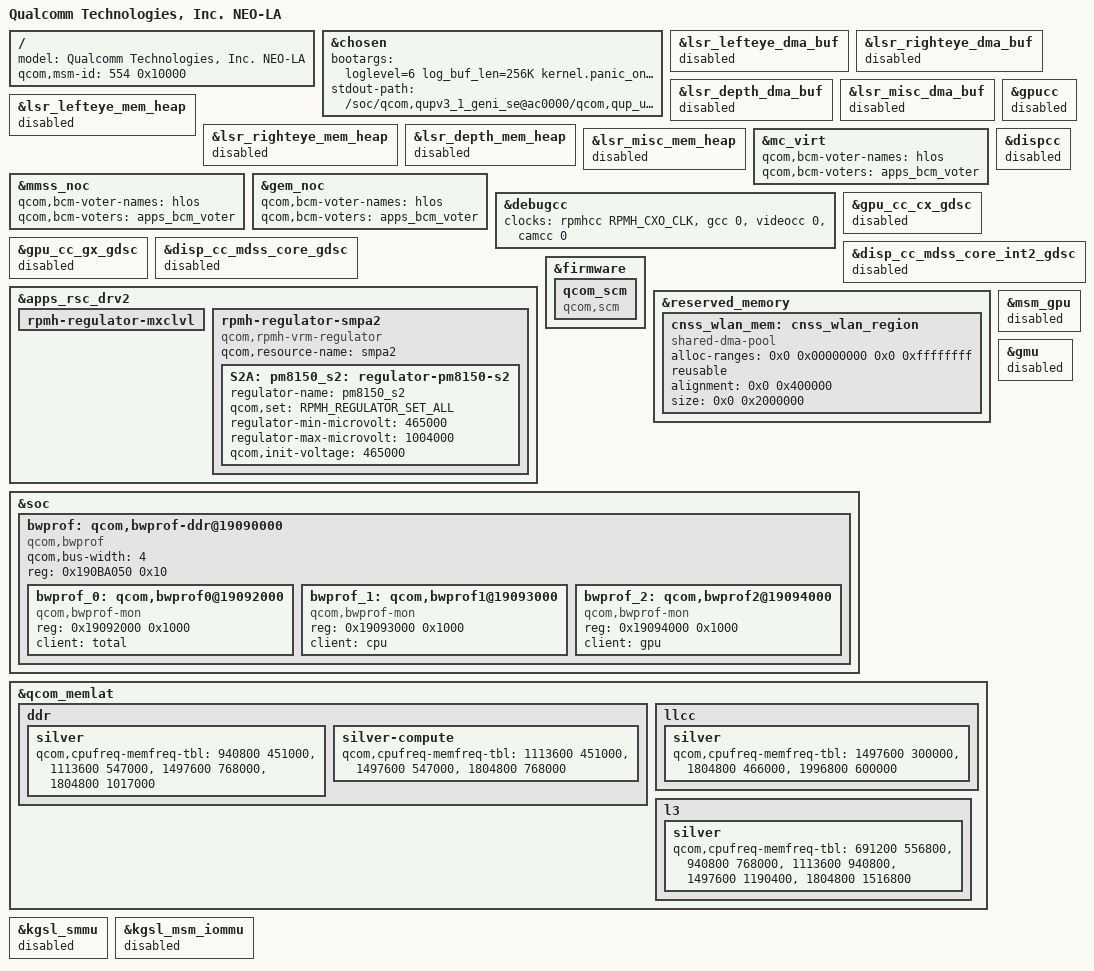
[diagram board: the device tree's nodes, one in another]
#include "neo.dtsi"
#include "neo_la-reserved-memory.dtsi"

/ {
	model = "Qualcomm Technologies, Inc. NEO-LA";
	qcom,msm-id = <554 0x10000>;
};

&chosen {
	bootargs = "loglevel=6 log_buf_len=256K kernel.panic_on_rcu_stall=1 loop.max_part=7 pcie_ports=compat service_locator.enable=1 msm_rtb.filter=0x237 allow_mismatched_32bit_el0 kasan=off rcupdate.rcu_expedited=1 rcu_nocbs=0-7 pstore.compress=none kpti=off swiotlb=noforce cgroup.memory=nokmem,nosocket allow_file_spec_access cpufreq.default_governor=performance disable_dma32=on ftrace_dump_on_oops";

	stdout-path = "/soc/qcom,qupv3_1_geni_se@ac0000/qcom,qup_uart@a94000:115200n8";
};

&lsr_lefteye_dma_buf {
	status = "disabled";
};

&lsr_righteye_dma_buf {
	status = "disabled";
};

&lsr_depth_dma_buf {
	status = "disabled";
};

&lsr_misc_dma_buf {
	status = "disabled";
};

&lsr_lefteye_mem_heap {
	status = "disabled";
};

&lsr_righteye_mem_heap {
	status = "disabled";
};

&lsr_depth_mem_heap {
	status = "disabled";
};

&lsr_misc_mem_heap {
	status = "disabled";
};

&mc_virt {
	qcom,bcm-voter-names = "hlos";
	qcom,bcm-voters = <&apps_bcm_voter>;
};

&mmss_noc {
	qcom,bcm-voter-names = "hlos";
	qcom,bcm-voters = <&apps_bcm_voter>;
};

&gem_noc {
	qcom,bcm-voter-names = "hlos";
	qcom,bcm-voters = <&apps_bcm_voter>;
};

&gpucc {
	status = "disabled";
};

&dispcc {
	status = "disabled";
};

&debugcc {
	/delete-property/ qcom,gpucc;
	/delete-property/ qcom,dispcc;
	clock-names = "xo_clk_src",
			"gcc",
			"videocc",
			"camcc";
	clocks = <&rpmhcc RPMH_CXO_CLK>,
		<&gcc 0>,
		<&videocc 0>,
		<&camcc 0>;
};

&gpu_cc_cx_gdsc {
	status = "disabled";
};

&gpu_cc_gx_gdsc {
	status = "disabled";
};

&disp_cc_mdss_core_gdsc {
	status = "disabled";
};

&disp_cc_mdss_core_int2_gdsc {
	status = "disabled";
};

&gpu_cc_gx_gdsc {
	/*
	 * Clocks uses GFX as its parent supply delete it as
	 * its not required on neo_la.
	 */
	/delete-property/ parent-supply;
};

&apps_rsc_drv2 {
	/* Delete GFX rail as it is not required on neo_la platform. */
	/delete-node/ rpmh-regulator-gfxlvl;

	rpmh-regulator-mxclvl {
		/delete-node/ regulator-pm8150-s8-gfx-voter-level;
	};

	rpmh-regulator-smpa2 {
		compatible = "qcom,rpmh-vrm-regulator";
		qcom,resource-name = "smpa2";
		S2A: pm8150_s2: regulator-pm8150-s2 {
			regulator-name = "pm8150_s2";
			qcom,set = <RPMH_REGULATOR_SET_ALL>;
			regulator-min-microvolt = <465000>;
			regulator-max-microvolt = <1004000>;
			qcom,init-voltage = <465000>;
		};
	};
};

&firmware {
	qcom_scm {
		compatible = "qcom,scm";
	};
};

&reserved_memory {
	cnss_wlan_mem: cnss_wlan_region {
		compatible = "shared-dma-pool";
		alloc-ranges = <0x0 0x00000000 0x0 0xffffffff>;
		reusable;
		alignment = <0x0 0x400000>;
		size = <0x0 0x2000000>;
	};
};

&soc {
	bwprof: qcom,bwprof-ddr@19090000 {
		compatible = "qcom,bwprof";
		#address-cells = <1>;
		#size-cells = <1>;
		qcom,bus-width = <4>;
		ranges;
		reg = <0x190BA050 0x10>;
		reg-names = "mem-freq";

		bwprof_0: qcom,bwprof0@19092000 {
			compatible = "qcom,bwprof-mon";
			reg = <0x19092000 0x1000>;
			reg-names = "base";
			client = "total";
		};

		bwprof_1: qcom,bwprof1@19093000 {
			compatible = "qcom,bwprof-mon";
			reg = <0x19093000 0x1000>;
			reg-names = "base";
			client = "cpu";
		};

		bwprof_2: qcom,bwprof2@19094000 {
			compatible = "qcom,bwprof-mon";
			reg = <0x19094000 0x1000>;
			reg-names = "base";
			client = "gpu";
		};
	};
};

&qcom_memlat {
	ddr {
		silver {
			qcom,cpufreq-memfreq-tbl =
					<  940800  451000 >,
					< 1113600  547000 >,
					< 1497600  768000 >,
					< 1804800 1017000 >;
		};

		silver-compute {
			qcom,cpufreq-memfreq-tbl =
					< 1113600  451000 >,
					< 1497600  547000 >,
					< 1804800  768000 >;
		};

	};

	llcc {
		silver {
			qcom,cpufreq-memfreq-tbl =
					< 1497600  300000 >,
					< 1804800  466000 >,
					< 1996800  600000 >;
		};
	};

	l3 {
		silver {
			qcom,cpufreq-memfreq-tbl =
					<  691200  556800 >,
					<  940800  768000 >,
					< 1113600  940800 >,
					< 1497600 1190400 >,
					< 1804800 1516800 >;
		};
	};
};

&kgsl_smmu {
	status = "disabled";
};

&msm_gpu {
	status = "disabled";
};

&kgsl_msm_iommu {
	status = "disabled";
};

&gmu {
	status = "disabled";
};
